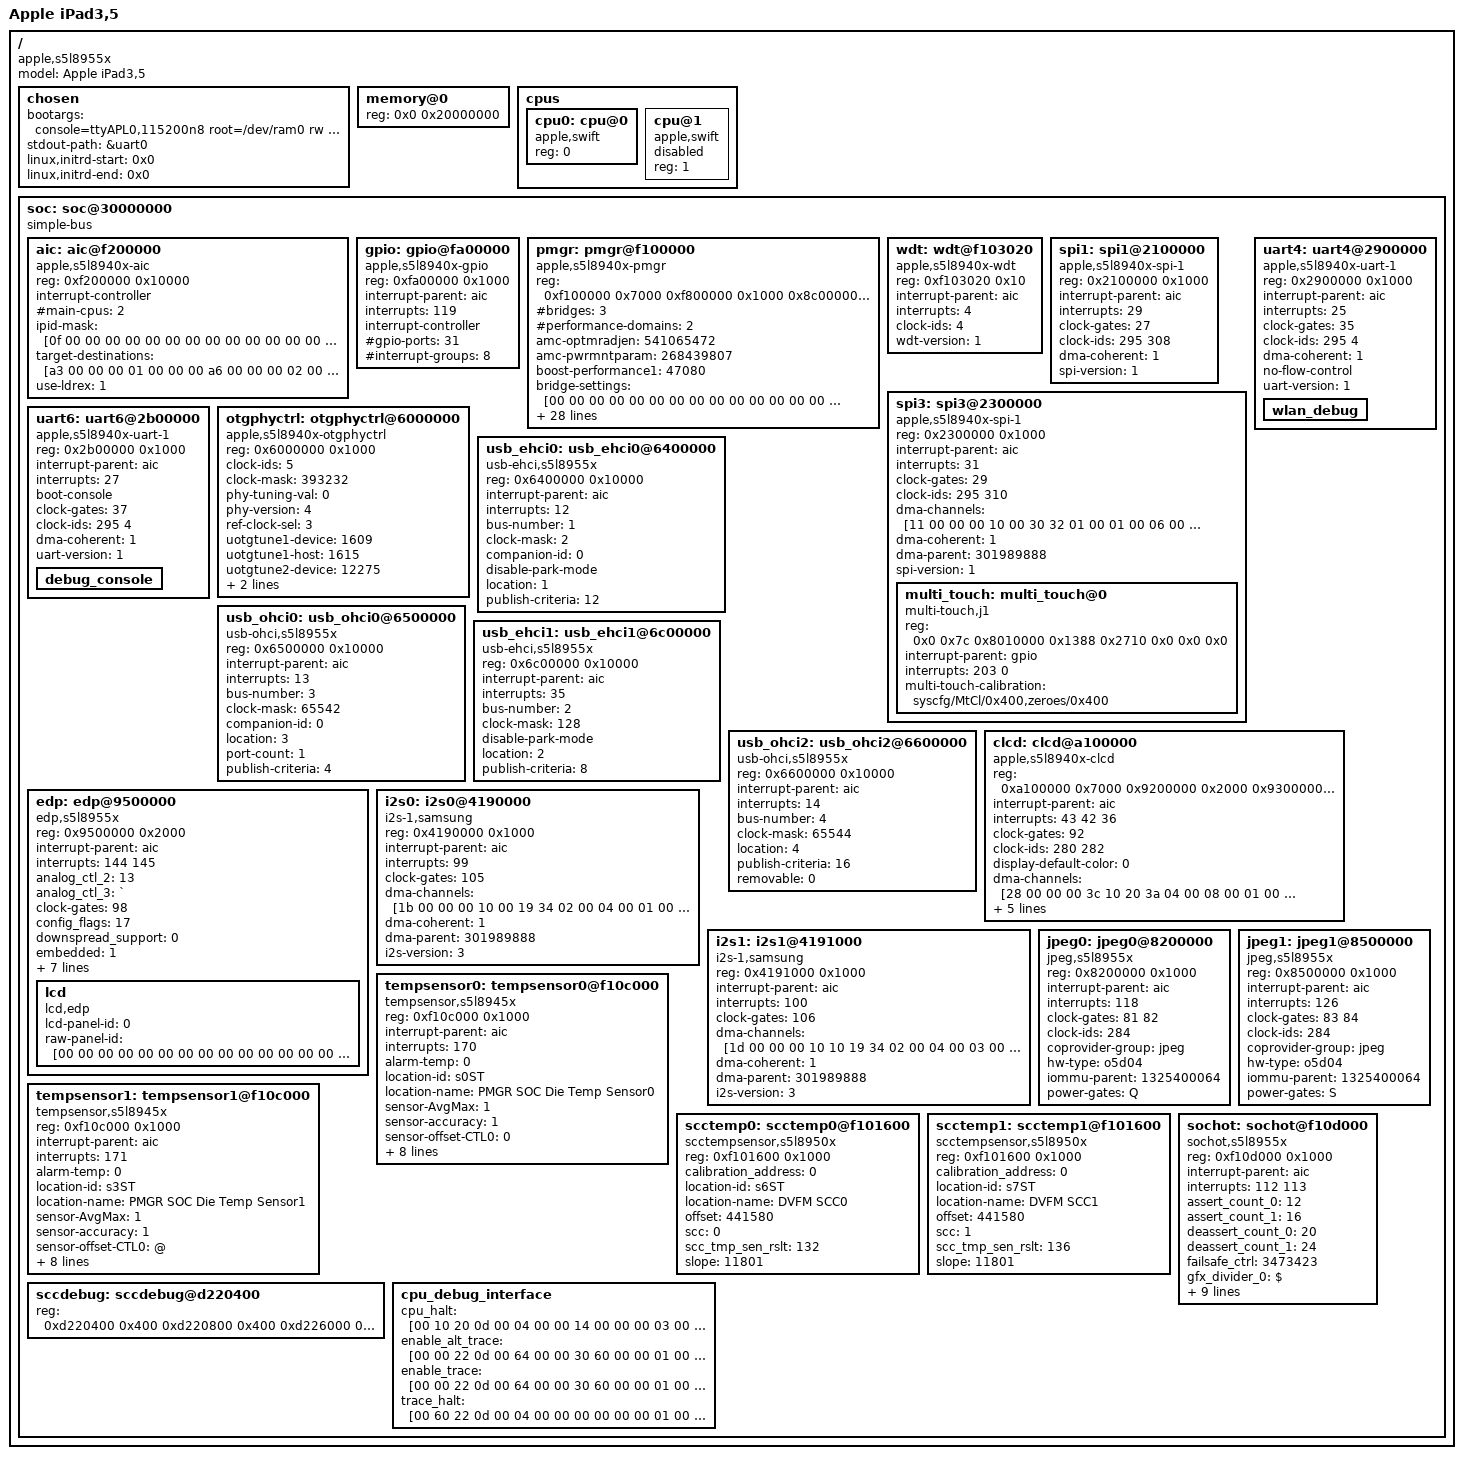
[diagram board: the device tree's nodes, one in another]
/*
 * Generated by adt_to_dts.py from Apple iBoot ADT.
 * Target: iPad2,5 (P105AP / S5L8942X, Apple A5).
 *
 * Register addresses under soc@30000000 use arm-io local bus
 * addresses (child 0 -> parent 0x30000000, size 0x10000000).
 * usb-complex children are flattened through usb-complex ranges
 * (child 0 -> 0x06100000, size 0x00600000) before insertion.
 *
 * memory@0, chosen/linux,initrd-*, and framebuffer values are zero
 * in the static ADT; patch them at boot from live iBoot state.
 */

/dts-v1/;

/ {
	compatible = "apple,s5l8955x", "apple,ipad3,5";
	model = "Apple iPad3,5";
	#address-cells = <1>;
	#size-cells = <1>;
	
	chosen {
		bootargs = "console=ttyAPL0,115200n8 root=/dev/ram0 rw earlyprintk";
		stdout-path = &uart0;
		linux,initrd-start = <0x0>;
		linux,initrd-end = <0x0>;
		/* ADT mac-address-bluetooth0 = [6d6163616464722f6274616464722c7379736366672f424d61632f36] */
		/* ADT mac-address-ethernet0 = [6d6163616464722f657468616464722c7379736366672f454d61632f36] */
		/* ADT mac-address-wifi0 = [6d6163616464722f77696669616464722c7379736366672f574d61632f36] */
	};
	
	memory@0 {
		device_type = "memory";
		reg = <0x0 0x20000000>; /* TODO: patch at boot; 512 MiB placeholder */
	};
	
	cpus {
		#address-cells = <1>;
		#size-cells = <0>;
		cpu0: cpu@0 {
			device_type = "cpu";
			compatible = "apple,swift";
			reg = <0>;
		};
		cpu@1 {
			device_type = "cpu";
			compatible = "apple,swift";
			reg = <1>;
			status = "disabled";
		};
	};
	
	soc: soc@30000000 {
		compatible = "simple-bus";
		#address-cells = <1>;
		#size-cells = <1>;
		ranges = <0x0 0x30000000 0x10000000>;
		
		aic: aic@f200000 {
			compatible = "apple,s5l8940x-aic";
			device_type = "interrupt-controller";
			reg = <0xf200000 0x10000>;
			interrupt-controller;
			#interrupt-cells = <1>;
			#address-cells = <0>;
			#main-cpus = <2>;
			ipid-mask = [0f 00 00 00 00 00 00 00 00 00 00 00 00 00 00 00 00 00 00 00 00 00 00 00];
			target-destinations = [a3 00 00 00 01 00 00 00 a6 00 00 00 02 00 00 00];
			use-ldrex = <1>;
		};
		
		gpio: gpio@fa00000 {
			compatible = "apple,s5l8940x-gpio", "apple,s5l8940x-gpio", "apple,s5l8940x-gpio";
			device_type = "interrupt-controller";
			reg = <0xfa00000 0x1000>;
			interrupt-parent = <&aic>;
			interrupts = <119>;
			interrupt-controller;
			#interrupt-cells = <2>;
			#address-cells = <0>;
			#gpio-ports = <31>;
			#interrupt-groups = <8>;
		};
		
		pmgr: pmgr@f100000 {
			compatible = "apple,s5l8940x-pmgr", "apple,s5l8940x-pmgr";
			reg = <0xf100000 0x7000 0xf800000 0x1000 0x8c00000 0x1000 0x8d00000 0x1000 0x8e00000 0x1000 0x8f00000 0x1000 0xa500000 0x1000 0xa600000 0x1000>;
			#bridges = <3>;
			#performance-domains = <2>;
			amc-optmradjen = <541065472>;
			amc-pwrmntparam = <268439807>;
			boost-performance1 = <47080>;
			bridge-settings = [00 00 00 00 00 00 00 00 00 00 00 00 00 00 00 00 00 00 00 00 00 00 00 00 00 00 00 00 00 00 00 00 00 00 00 00 00 00 00 00 00 00 00 00 00 00 00 00 00 00 00 00 00 00 00 00 00 00 00 00 00 00 00 00 00 00 00 00 00 00 00 00 00 00 00 00 00 00 00 00 00 00 00 00 00 00 00 00 00 00 00 00 00 00 00 00 00 00 00 00 00 00 00 00 00 00 00 00 00 00 00 00 00 00 00 00 00 00 00 00 00 00 00 00 00 00 00 00 00 00 00 00 00 00 00 00 00 00 00 00 00 00 00 00 00 00 00 00 00 00 00 00 00 00 00 00 00 00 00 00 00 00 00 00 00 00 00 00 00 00 00 00 00 00 00 00 00 00 00 00 00 00 00 00 00 00 00 00 00 00 00 00 00 00 00 00 00 00 00 00 00 00 00 00 00 00 00 00 00 00 00 00 00 00 00 00 00 00 00 00 00 00 00 00 00 00 00 00 00 00 00 00 00 00 00 00 00 00 00 00 00 00 00 00 00 00 00 00 00 00 00 00 00 00 00 00 00 00 00 00 00 00 00 00 00 00 00 00 00 00 00 00 00 00 00 00 00 00 00 00 00 00 00 00 00 00 00 00 00 00 00 00 00 00 00 00 00 00 00 00 00 00 00 00 00 00 00 00 00 00 00 00 00 00 00 00 00 00 00 00 00 00 00 00 00 00 00 00 00 00 00 00 00 00 00 00 00 00 00 00 00 00 00 00 00 00 00 00 00 00 00 00 00 00 00 00 00 00 00 00 00 00 00 00 00 00 00 00 00 00 00 00 00 00 00 00 00 00 00 00 00 00 00 00 00 00 00 00 00 00 00 00 00 00 00 00 00 00 00 00 00 00 00 00 00 00 00 00 00 00 00 00 00 00 00 00 00 00 00 00 00 00 00 00 00 00 00 00 00 00 00 00 00 00 00 00 00 00 00 00 00 00 00 00 00 00 00 00 00 00 00 00 00 00 00 00 00 00 00 00 00 00 00 00 00 00 00 00 00 00 00 00 00 00 00 00 00 00 00 00 00 00 00 00 00 00 00 00 00 00 00 00 00 00 00 00 00 00 00 00 00 00 00 00 00 00 00 00 00 00 00 00];
			clock-ids = <317 318 319>;
			cpu-max-core-count = <2>;
			device-clocks = [08 00 00 00 00 00 00 00 00 00 00 00 00 00 00 00 00 00 00 00 ed 7c 00 00 00 00 00 00 43 50 55 30 00 00 00 00 00 00 00 00 00 00 00 00 00 00 00 01 00 00 00 00 00 00 00 00 00 00 00 00 00 00 00 00 ed 7c 00 00 00 00 00 00 43 50 55 31 00 00 00 00 00 00 00 00 00 00 00 00 00 00 00 08 02 01 00 00 00 00 00 00 0b 00 00 00 00 00 00 00 00 00 00 00 00 00 00 00 48 50 45 52 46 2d 4e 52 54 00 00 00 00 00 00 00 00 00 00 09 02 02 00 00 00 00 00 00 13 18 00 00 00 00 00 00 00 00 00 00 00 00 00 00 48 50 45 52 46 2d 52 54 00 00 00 00 00 00 00 00 00 00 00 0a 00 00 00 00 09 00 00 00 14 00 00 00 00 00 00 00 00 00 00 00 00 00 00 00 48 50 45 52 46 2d 49 53 50 00 00 00 00 00 00 00 00 00 00 0b 00 00 00 00 00 00 00 00 28 00 00 00 00 00 00 00 00 00 05 00 00 00 00 00 41 55 44 49 4f 00 00 00 00 00 00 00 00 00 00 00 01 00 08 0e 00 00 00 00 00 00 00 00 00 00 00 00 00 00 00 00 00 00 00 00 00 00 00 00 52 47 42 4f 55 54 2d 4c 41 52 47 45 00 00 00 00 01 00 08 0f 00 00 00 00 00 00 00 00 00 00 00 00 00 00 00 00 00 00 00 00 00 00 00 00 44 55 41 4c 2d 44 49 53 50 4c 41 59 00 00 00 00 00 00 00 10 00 00 00 00 00 00 00 00 2f 00 00 00 00 00 00 00 00 00 00 00 00 00 00 00 53 44 49 4f 00 00 00 00 00 00 00 00 00 00 00 00 00 00 00 11 00 00 00 00 00 00 00 00 30 00 00 00 00 00 00 00 00 00 00 00 00 00 00 00 53 48 41 2d 31 00 00 00 00 00 00 00 00 00 00 00 00 00 00 12 00 00 00 00 00 00 00 00 31 00 00 00 00 00 00 00 00 00 00 00 00 00 00 00 53 48 41 2d 32 00 00 00 00 00 00 00 00 00 00 00 01 00 00 14 00 00 00 00 00 00 00 00 32 00 00 00 00 00 00 00 00 00 00 00 00 00 00 00 46 4d 49 30 00 00 00 00 00 00 00 00 00 00 00 00 00 00 00 15 00 00 00 00 00 00 00 00 33 00 00 00 00 00 00 00 00 00 00 00 00 00 00 00 46 4d 49 30 2d 42 43 48 00 00 00 00 00 00 00 00 01 00 00 16 00 00 00 00 00 00 00 00 34 00 00 00 00 00 00 00 00 00 00 00 00 00 00 00 46 4d 49 31 00 00 00 00 00 00 00 00 00 00 00 00 00 00 00 17 00 00 00 00 00 00 00 00 35 00 00 00 00 00 00 00 00 00 00 00 00 00 00 00 46 4d 49 31 2d 42 43 48 00 00 00 00 00 00 00 00 00 00 00 18 00 00 00 00 00 00 00 00 36 00 00 00 00 00 00 00 00 00 00 00 00 00 00 00 46 4d 49 2d 44 4c 4c 00 00 00 00 00 00 00 00 00 00 00 00 1a 00 00 00 00 00 00 00 00 39 00 00 00 00 00 00 00 00 00 00 00 00 00 00 00 53 50 49 30 00 00 00 00 00 00 00 00 00 00 00 00 00 00 00 1b 00 00 00 00 00 00 00 00 3a 00 00 00 00 00 00 00 00 00 00 00 00 00 00 00 53 50 49 31 00 00 00 00 00 00 00 00 00 00 00 00 00 00 00 1c 00 00 00 00 00 00 00 00 3b 00 00 00 00 00 00 00 00 00 00 00 00 00 00 00 53 50 49 32 00 00 00 00 00 00 00 00 00 00 00 00 00 00 00 1d 00 00 00 00 00 00 00 00 3c 00 00 00 00 00 00 00 00 00 00 00 00 00 00 00 53 50 49 33 00 00 00 00 00 00 00 00 00 00 00 00 00 00 00 1e 00 00 00 00 00 00 00 00 3d 00 00 00 00 00 00 00 00 00 00 00 00 00 00 00 53 50 49 34 00 00 00 00 00 00 00 00 00 00 00 00 00 00 03 1f 00 00 00 00 00 00 00 00 3e 00 00 00 00 00 00 00 00 00 00 00 00 00 00 00 55 41 52 54 30 00 00 00 00 00 00 00 00 00 00 00 00 00 00 20 00 00 00 00 00 00 00 00 3f 00 00 00 00 00 00 00 00 00 00 00 00 00 00 00 55 41 52 54 31 00 00 00 00 00 00 00 00 00 00 00 00 00 00 21 00 00 00 00 00 00 00 00 40 00 00 00 00 00 00 00 00 00 00 00 00 00 00 00 55 41 52 54 32 00 00 00 00 00 00 00 00 00 00 00 00 00 00 22 00 00 00 00 00 00 00 00 41 00 00 00 00 00 00 00 00 00 00 00 00 00 00 00 55 41 52 54 33 00 00 00 00 00 00 00 00 00 00 00 00 00 00 23 00 00 00 00 00 00 00 00 42 00 00 00 00 00 00 00 00 00 00 00 00 00 00 00 55 41 52 54 34 00 00 00 00 00 00 00 00 00 00 00 00 00 00 24 00 00 00 00 00 00 00 00 43 00 00 00 00 00 00 00 00 00 00 00 00 00 00 00 55 41 52 54 35 00 00 00 00 00 00 00 00 00 00 00 00 00 03 25 00 00 00 00 00 00 00 00 44 00 00 00 00 00 00 00 00 00 00 00 00 00 00 00 55 41 52 54 36 00 00 00 00 00 00 00 00 00 00 00 00 00 00 28 00 00 00 00 00 00 00 00 45 00 00 00 00 00 00 00 00 00 00 00 00 00 00 00 50 4b 45 00 00 00 00 00 00 00 00 00 00 00 00 00 00 00 00 29 00 00 00 00 00 00 00 00 46 00 00 00 00 00 00 00 00 00 00 00 00 00 00 00 49 32 43 30 00 00 00 00 00 00 00 00 00 00 00 00 00 00 00 2a 00 00 00 00 00 00 00 00 47 00 00 00 00 00 00 00 00 00 00 00 00 00 00 00 49 32 43 31 00 00 00 00 00 00 00 00 00 00 00 00 00 00 00 2b 00 00 00 00 00 00 00 00 48 00 00 00 00 00 00 00 00 00 00 00 00 00 00 00 49 32 43 32 00 00 00 00 00 00 00 00 00 00 00 00 00 00 00 2c 00 00 00 00 00 00 00 00 49 00 00 00 00 00 00 00 00 00 00 00 00 00 00 00 50 57 4d 00 00 00 00 00 00 00 00 00 00 00 00 00 00 00 03 30 00 00 00 00 00 00 00 00 1e 00 00 00 00 00 00 00 51 f8 3d 00 00 00 00 00 43 44 49 4f 00 00 00 00 00 00 00 00 00 00 00 00 00 00 03 31 00 00 00 00 00 00 00 00 1f 00 00 00 00 00 00 00 00 00 00 00 00 00 00 00 43 44 4d 41 00 00 00 00 00 00 00 00 00 00 00 00 00 00 10 32 00 00 00 00 00 00 00 00 20 00 00 00 00 00 00 00 00 00 00 00 00 00 00 00 49 4f 50 00 00 00 00 00 00 00 00 00 00 00 00 00 00 00 00 04 00 00 00 00 00 00 00 00 21 00 00 00 00 00 00 00 00 00 00 00 00 00 00 00 55 50 45 52 46 00 00 00 00 00 00 00 00 00 00 00 05 00 00 05 00 00 00 00 04 00 00 00 24 00 00 00 00 00 00 00 00 00 00 00 00 00 00 00 55 53 42 31 31 48 4f 53 54 00 00 00 00 00 00 00 00 00 00 06 00 00 00 00 04 00 00 00 27 00 00 00 00 00 00 00 00 00 00 00 00 00 00 00 55 53 42 52 45 47 30 00 00 00 00 00 00 00 00 00 00 00 00 07 00 00 00 00 00 00 00 00 00 00 00 00 5a 00 00 00 00 00 00 00 00 00 00 00 55 53 42 2d 46 52 45 45 2d 43 4c 4b 00 00 00 00 00 00 00 34 00 00 00 00 04 06 00 00 00 00 00 00 00 00 00 00 00 00 00 00 00 00 00 00 55 53 42 2d 50 48 59 00 00 00 00 00 00 00 00 00 01 00 00 35 00 00 00 00 04 00 00 00 22 00 00 00 00 00 00 00 00 00 00 00 00 00 00 00 55 53 42 4f 54 47 30 00 00 00 00 00 00 00 00 00 00 00 00 36 00 00 00 00 04 07 00 00 23 00 00 00 00 00 00 00 00 00 00 00 00 00 00 00 55 53 42 32 48 4f 53 54 30 00 00 00 00 00 00 00 00 00 00 37 00 00 00 00 04 06 00 00 25 00 00 00 00 00 00 00 00 00 00 00 00 00 00 00 55 53 42 32 48 4f 53 54 30 5f 4f 48 43 49 00 00 00 00 00 38 00 00 00 00 04 05 06 00 26 00 00 00 00 00 00 00 00 00 00 00 00 00 00 00 55 53 42 31 31 48 4f 53 54 5f 4f 48 43 49 00 00 00 00 00 3a 00 00 00 00 04 07 00 00 50 00 00 00 00 00 00 00 00 00 00 00 00 00 00 00 55 53 42 32 48 4f 53 54 31 00 00 00 00 00 00 00 00 00 00 3b 00 00 00 00 04 06 00 00 51 00 00 00 00 00 00 00 00 00 00 00 00 00 00 00 55 53 42 32 48 4f 53 54 31 5f 4f 48 43 49 00 00 00 00 00 3c 00 00 00 00 00 00 00 00 00 00 00 00 53 00 00 00 00 00 00 00 00 00 00 00 55 53 42 2d 50 48 59 30 2d 43 4c 4b 00 00 00 00 00 00 00 3d 00 00 00 00 00 00 00 00 00 00 00 00 59 00 00 00 00 00 00 00 00 00 00 00 55 53 42 2d 50 48 59 31 2d 43 4c 4b 00 00 00 00 01 00 00 3e 00 00 00 00 00 00 00 00 00 00 00 00 00 00 00 00 00 00 00 00 00 00 00 00 55 53 42 32 2d 46 41 53 54 00 00 00 00 00 00 00 01 00 00 40 00 00 00 00 00 00 00 00 09 0a 00 00 00 00 00 00 00 00 c4 09 00 00 00 00 47 46 58 00 00 00 00 00 00 00 00 00 00 00 00 00 80 00 00 41 00 00 00 00 00 00 00 00 00 00 00 00 00 00 00 00 00 00 00 00 00 00 00 00 47 46 58 2d 46 41 53 54 00 00 00 00 00 00 00 00 00 00 00 48 02 00 00 00 08 00 00 00 00 00 00 00 00 00 00 00 00 00 00 00 00 00 00 00 44 41 52 54 2d 4e 52 54 00 00 00 00 00 00 00 00 01 00 00 49 00 00 00 00 08 00 00 00 0c 00 00 00 00 00 00 00 00 00 00 00 00 00 00 00 56 44 45 43 00 00 00 00 00 00 00 00 00 00 00 00 80 00 00 4a 00 00 00 00 00 00 00 00 00 00 00 00 00 00 00 00 00 00 00 00 00 00 00 00 56 44 45 43 2d 46 41 53 54 00 00 00 00 00 00 00 01 00 00 4b 00 00 00 00 08 00 00 00 12 00 00 00 00 00 00 00 00 00 64 00 00 00 00 00 56 45 4e 43 00 00 00 00 00 00 00 00 00 00 00 00 80 01 00 4c 00 00 00 00 00 00 00 00 00 00 00 00 00 00 00 00 00 00 64 00 00 00 00 00 56 45 4e 43 2d 46 41 53 54 00 00 00 00 00 00 00 01 00 00 4d 00 00 00 00 08 00 00 00 0d 00 00 00 00 00 00 00 00 00 00 00 00 00 00 00 53 43 41 4c 45 52 30 00 00 00 00 00 00 00 00 00 80 00 00 4e 00 00 00 00 00 00 00 00 00 00 00 00 00 00 00 00 00 00 00 00 00 00 00 00 53 43 41 4c 45 52 30 2d 46 41 53 54 00 00 00 00 01 00 00 4f 00 00 00 00 08 00 00 00 0e 00 00 00 00 00 00 00 00 00 00 00 00 00 00 00 53 43 41 4c 45 52 31 00 00 00 00 00 00 00 00 00 80 00 00 50 00 00 00 00 00 00 00 00 00 00 00 00 00 00 00 00 00 00 00 00 00 00 00 00 53 43 41 4c 45 52 31 2d 46 41 53 54 00 00 00 00 01 00 00 51 00 00 00 00 08 00 00 00 0f 00 00 00 00 00 00 00 00 00 00 00 00 00 00 00 4a 50 45 47 30 00 00 00 00 00 00 00 00 00 00 00 80 00 00 52 00 00 00 00 00 00 00 00 00 00 00 00 00 00 00 00 00 00 00 00 00 00 00 00 4a 50 45 47 30 2d 46 41 53 54 00 00 00 00 00 00 01 00 00 53 00 00 00 00 08 00 00 00 10 00 00 00 00 00 00 00 00 00 00 00 00 00 00 00 4a 50 45 47 31 00 00 00 00 00 00 00 00 00 00 00 80 00 00 54 00 00 00 00 00 00 00 00 00 00 00 00 00 00 00 00 00 00 00 00 00 00 00 00 4a 50 45 47 31 2d 46 41 53 54 00 00 00 00 00 00 00 00 01 5c 03 00 00 00 09 0f 00 00 16 1a 00 00 00 00 00 00 00 00 c4 01 00 00 00 00 43 4c 43 44 00 00 00 00 00 00 00 00 00 00 00 00 00 00 01 5e 03 00 00 00 09 0e 0f 00 17 1c 00 00 00 00 00 00 00 00 00 00 00 00 00 00 52 47 42 4f 55 54 00 00 00 00 00 00 00 00 00 00 00 00 04 5f 00 00 00 00 0e 00 00 00 00 00 00 00 00 00 00 00 00 00 00 00 00 00 00 00 52 47 42 4f 55 54 2d 53 4d 41 4c 4c 00 00 00 00 00 00 01 60 00 00 00 00 09 00 00 00 1d 00 00 00 00 00 00 00 00 00 00 00 00 00 00 00 44 50 4c 49 4e 4b 00 00 00 00 00 00 00 00 00 00 00 00 00 61 00 00 00 00 09 00 00 00 1b 00 00 00 00 00 00 00 00 00 00 00 00 00 00 00 54 56 2d 4f 55 54 00 00 00 00 00 00 00 00 00 00 00 00 01 62 00 00 00 00 09 00 00 00 15 00 00 00 00 00 00 00 00 00 00 00 00 00 00 00 45 44 50 00 00 00 00 00 00 00 00 00 00 00 00 00 00 00 00 64 00 00 00 00 0a 00 00 00 00 00 00 00 00 00 00 00 00 00 00 00 00 00 00 00 44 41 52 54 2d 52 54 00 00 00 00 00 00 00 00 00 01 00 10 65 00 00 00 00 0a 00 00 00 00 00 00 00 00 00 00 00 00 00 c8 00 00 00 00 00 49 53 50 00 00 00 00 00 00 00 00 00 00 00 00 00 00 00 10 68 00 00 00 00 0b 00 00 00 00 00 00 00 00 00 00 00 00 00 00 00 00 00 00 00 41 45 32 00 00 00 00 00 00 00 00 00 00 00 00 00 00 00 00 69 00 00 00 00 0b 00 00 00 29 00 00 00 00 00 00 00 00 00 00 00 00 00 00 00 49 32 53 30 00 00 00 00 00 00 00 00 00 00 00 00 00 00 00 6a 00 00 00 00 0b 00 00 00 2a 00 00 00 00 00 00 00 00 00 00 00 00 00 00 00 49 32 53 31 00 00 00 00 00 00 00 00 00 00 00 00 00 00 00 6b 00 00 00 00 0b 00 00 00 2b 00 00 00 00 00 00 00 00 00 00 00 00 00 00 00 49 32 53 32 00 00 00 00 00 00 00 00 00 00 00 00 00 00 00 6c 00 00 00 00 0b 00 00 00 2c 00 00 00 00 00 00 00 00 00 00 00 00 00 00 00 49 32 53 33 2f 4d 43 41 31 00 00 00 00 00 00 00 00 00 00 6d 00 00 00 00 0b 00 00 00 2d 00 00 00 00 00 00 00 00 00 00 00 00 00 00 00 53 50 44 49 46 00 00 00 00 00 00 00 00 00 00 00 00 00 00 6e 00 00 00 00 0b 00 00 00 38 00 00 00 00 00 00 00 00 00 00 00 00 00 00 00 4d 43 41 00 00 00 00 00 00 00 00 00 00 00 00 00 05 00 00 7e 00 00 00 00 00 00 00 00 4c 00 00 00 00 00 00 00 00 00 00 00 00 00 00 00 53 57 49 00 00 00 00 00 00 00 00 00 00 00 00 00 00 00 03 7f 00 00 00 00 00 00 00 00 4d 00 00 00 00 00 00 00 00 00 00 00 00 00 00 00 44 57 49 00 00 00 00 00 00 00 00 00 00 00 00 00];
			device-clocks-max = <128>;
			device-clocks-min = <16>;
			dvb-boost-timeout = <4000>;
			dvb-relax-timeout = <12000>;
			dvb-thermal-period = <1000000>;
			dvc-active-timeout = <4000>;
			dvc-grace-period = "d";
			dvd-period = <8000>;
			dvd-threshold = <1000>;
			firmware-m-perf-states = [00 00 00 00 00 00 00 00 00 00 00 00 00 00 00 00];
			firmware-p-perf-state = <0>;
			firmware-v-perf-states = [00 00 00 00 00 00 00 00];
			nominal-performance0 = <65536>;
			nominal-performance1 = <54613>;
			pdmvr-rules = <16842754>;
			performance-domain-features = [01 00 01 00 00 07 01 00];
			turbolag-timeout = <100000>;
			voltage-states0 = [00 00 01 00 00 00 00 00 00 80 00 00 00 00 00 00];
			voltage-states1 = [00 00 00 00 00 00 00 00 00 00 00 00 00 00 00 00 00 00 00 00 00 00 00 00 00 00 00 00 00 00 00 00 00 00 00 00 00 00 00 00 00 00 00 00 00 00 00 00 00 00 00 00 00 00 00 00 00 00 00 00 00 00 00 00];
		};
		
		wdt: wdt@f103020 {
			compatible = "apple,s5l8940x-wdt", "apple,s5l8940x-wdt", "apple,s5l8940x-wdt", "apple,s5l8940x-wdt";
			device_type = "wdt";
			reg = <0xf103020 0x10>;
			interrupt-parent = <&aic>;
			interrupts = <4>;
			clock-ids = <4>;
			wdt-version = <1>;
		};
		
		spi1: spi1@2100000 {
			compatible = "apple,s5l8940x-spi-1";
			device_type = "spi";
			reg = <0x2100000 0x1000>;
			interrupt-parent = <&aic>;
			interrupts = <29>;
			#address-cells = <1>;
			#size-cells = <7>;
			clock-gates = <27>;
			clock-ids = <295 308>;
			dma-coherent = <1>;
			spi-version = <1>;
		};
		
		spi3: spi3@2300000 {
			compatible = "apple,s5l8940x-spi-1";
			device_type = "spi";
			reg = <0x2300000 0x1000>;
			interrupt-parent = <&aic>;
			interrupts = <31>;
			#address-cells = <1>;
			#size-cells = <7>;
			clock-gates = <29>;
			clock-ids = <295 310>;
			dma-channels = [11 00 00 00 10 00 30 32 01 00 01 00 06 00 00 00 12 00 00 00 20 00 40 32 01 00 01 00 07 00 00 00];
			dma-coherent = <1>;
			dma-parent = <301989888>;
			spi-version = <1>;
			multi_touch: multi_touch@0 {
				compatible = "multi-touch,j1";
				device_type = "multi-touch";
				reg = <0x0 0x7c 0x8010000 0x1388 0x2710 0x0 0x0 0x0>;
				interrupt-parent = <&gpio>;
				interrupts = <203 0>;
				multi-touch-calibration = "syscfg/MtCl/0x400,zeroes/0x400";
			};
			
		};
		
		uart4: uart4@2900000 {
			compatible = "apple,s5l8940x-uart-1";
			device_type = "uart";
			reg = <0x2900000 0x1000>;
			interrupt-parent = <&aic>;
			interrupts = <25>;
			clock-gates = <35>;
			clock-ids = <295 4>;
			dma-coherent = <1>;
			no-flow-control;
			uart-version = <1>;
			wlan_debug: wlan_debug {
				device_type = "wlan-debug";
			};
			
		};
		
		uart6: uart6@2b00000 {
			compatible = "apple,s5l8940x-uart-1";
			device_type = "uart";
			reg = <0x2b00000 0x1000>;
			interrupt-parent = <&aic>;
			interrupts = <27>;
			boot-console;
			clock-gates = <37>;
			clock-ids = <295 4>;
			dma-coherent = <1>;
			uart-version = <1>;
			debug_console: debug_console {
			};
			
		};
		
		otgphyctrl: otgphyctrl@6000000 {
			compatible = "apple,s5l8940x-otgphyctrl", "apple,s5l8940x-otgphyctrl", "apple,s5l8940x-otgphyctrl";
			device_type = "otgphyctrl";
			reg = <0x6000000 0x1000>;
			clock-ids = <5>;
			clock-mask = <393232>;
			phy-tuning-val = <0>;
			phy-version = <4>;
			ref-clock-sel = <3>;
			uotgtune1-device = <1609>;
			uotgtune1-host = <1615>;
			uotgtune2-device = <12275>;
			uotgtune2-host = <28147>;
			usbhostset-en-incrx = <224>;
		};
		
		usb_ehci0: usb_ehci0@6400000 {
			compatible = "usb-ehci,s5l8955x", "usb-ehci,s5l8950x", "usb-synopsys_ehci,s5l8930x";
			device_type = "usb-ehci";
			reg = <0x6400000 0x10000>;
			interrupt-parent = <&aic>;
			interrupts = <12>;
			bus-number = <1>;
			clock-mask = <2>;
			companion-id = <0>;
			disable-park-mode;
			location = <1>;
			publish-criteria = <12>;
		};
		
		usb_ohci0: usb_ohci0@6500000 {
			compatible = "usb-ohci,s5l8955x", "usb-ohci,s5l8950x", "usb-ohci,s5l8930x";
			device_type = "usb-ohci";
			reg = <0x6500000 0x10000>;
			interrupt-parent = <&aic>;
			interrupts = <13>;
			bus-number = <3>;
			clock-mask = <65542>;
			companion-id = <0>;
			location = <3>;
			port-count = <1>;
			publish-criteria = <4>;
		};
		
		usb_ehci1: usb_ehci1@6c00000 {
			compatible = "usb-ehci,s5l8955x", "usb-ehci,s5l8950x", "usb-synopsys_ehci,s5l8930x";
			device_type = "usb-ehci";
			reg = <0x6c00000 0x10000>;
			interrupt-parent = <&aic>;
			interrupts = <35>;
			bus-number = <2>;
			clock-mask = <128>;
			disable-park-mode;
			location = <2>;
			publish-criteria = <8>;
		};
		
		usb_ohci2: usb_ohci2@6600000 {
			compatible = "usb-ohci,s5l8955x", "usb-ohci,s5l8950x", "usb-ohci,s5l8930x";
			device_type = "usb-ohci";
			reg = <0x6600000 0x10000>;
			interrupt-parent = <&aic>;
			interrupts = <14>;
			bus-number = <4>;
			clock-mask = <65544>;
			location = <4>;
			publish-criteria = <16>;
			removable = <0>;
		};
		
		clcd: clcd@a100000 {
			compatible = "apple,s5l8940x-clcd";
			device_type = "clcd";
			reg = <0xa100000 0x7000 0x9200000 0x2000 0x9300000 0x1000 0x9900000 0x1000 0x9380000 0x1000 0x9a00000 0x7000 0x9b00000 0x4000>;
			interrupt-parent = <&aic>;
			interrupts = <43 42 36>;
			clock-gates = <92>;
			clock-ids = <280 282>;
			display-default-color = <0>;
			dma-channels = [28 00 00 00 3c 10 20 3a 04 00 08 00 01 00 00 00];
			dma-coherent = [00 00 00 00 01 00 00 00];
			dma-parent = <301989888>;
			dot-pitch = <0>;
			enable-aap;
			power-gates = "\\";
		};
		
		edp: edp@9500000 {
			compatible = "edp,s5l8955x", "edp,s5l8945x";
			device_type = "edp";
			reg = <0x9500000 0x2000>;
			interrupt-parent = <&aic>;
			interrupts = <144 145>;
			analog_ctl_2 = <13>;
			analog_ctl_3 = "`";
			clock-gates = <98>;
			config_flags = <17>;
			downspread_support = <0>;
			embedded = <1>;
			max_lane_count = <4>;
			max_link_rate = <10>;
			min_lane_count = <4>;
			min_link_rate = <6>;
			pll_ctl = <20>;
			power-gates = "b";
			pre_configured = <0>;
			lcd: lcd {
				compatible = "lcd,edp";
				device_type = "lcd";
				#address-cells = <1>;
				#size-cells = <1>;
				lcd-panel-id = <0>;
				raw-panel-id = [00 00 00 00 00 00 00 00 00 00 00 00 00 00 00 00];
			};
			
		};
		
		i2s0: i2s0@4190000 {
			compatible = "i2s-1,samsung";
			device_type = "i2s";
			reg = <0x4190000 0x1000>;
			interrupt-parent = <&aic>;
			interrupts = <99>;
			#address-cells = <0>;
			#size-cells = <8>;
			clock-gates = <105>;
			dma-channels = [1b 00 00 00 10 00 19 34 02 00 04 00 01 00 00 00 1c 00 00 00 38 00 19 34 02 00 04 00 00 00 00 00 1b 00 00 00 10 00 19 34 04 00 04 00 01 00 00 00 1c 00 00 00 38 00 19 34 04 00 04 00 00 00 00 00];
			dma-coherent = <1>;
			dma-parent = <301989888>;
			i2s-version = <3>;
		};
		
		i2s1: i2s1@4191000 {
			compatible = "i2s-1,samsung";
			device_type = "i2s";
			reg = <0x4191000 0x1000>;
			interrupt-parent = <&aic>;
			interrupts = <100>;
			#address-cells = <0>;
			#size-cells = <8>;
			clock-gates = <106>;
			dma-channels = [1d 00 00 00 10 10 19 34 02 00 04 00 03 00 00 00 1e 00 00 00 38 10 19 34 02 00 04 00 02 00 00 00 1d 00 00 00 10 10 19 34 04 00 04 00 03 00 00 00 1e 00 00 00 38 10 19 34 04 00 04 00 02 00 00 00];
			dma-coherent = <1>;
			dma-parent = <301989888>;
			i2s-version = <3>;
		};
		
		jpeg0: jpeg0@8200000 {
			compatible = "jpeg,s5l8955x", "jpeg,s5l8950x", "jpeg,s5l8920x";
			device_type = "jpeg";
			reg = <0x8200000 0x1000>;
			interrupt-parent = <&aic>;
			interrupts = <118>;
			clock-gates = <81 82>;
			clock-ids = <284>;
			coprovider-group = "jpeg";
			hw-type = "o5d04";
			iommu-parent = <1325400064>;
			power-gates = "Q";
		};
		
		jpeg1: jpeg1@8500000 {
			compatible = "jpeg,s5l8955x", "jpeg,s5l8950x", "jpeg,s5l8920x";
			device_type = "jpeg";
			reg = <0x8500000 0x1000>;
			interrupt-parent = <&aic>;
			interrupts = <126>;
			clock-gates = <83 84>;
			clock-ids = <284>;
			coprovider-group = "jpeg";
			hw-type = "o5d04";
			iommu-parent = <1325400064>;
			power-gates = "S";
		};
		
		tempsensor0: tempsensor0@f10c000 {
			compatible = "tempsensor,s5l8945x";
			device_type = "tempsensor0";
			reg = <0xf10c000 0x1000>;
			interrupt-parent = <&aic>;
			interrupts = <170>;
			alarm-temp = <0>;
			location-id = "s0ST";
			location-name = "PMGR SOC Die Temp Sensor0";
			sensor-AvgMax = <1>;
			sensor-accuracy = <1>;
			sensor-offset-CTL0 = <0>;
			sensor-offset-CTL1 = <4>;
			sensor-offset-CTL2 = <8>;
			sensor-offset-fuseslope = <12>;
			sensor-offset-readBK = <16>;
			sensor-offset-readBK1 = <20>;
			sensor-offset-readCnt = <28>;
			sensor-offset-readSum = <24>;
			sensor-offset-statMask = <16>;
		};
		
		tempsensor1: tempsensor1@f10c000 {
			compatible = "tempsensor,s5l8945x";
			device_type = "tempsensor1";
			reg = <0xf10c000 0x1000>;
			interrupt-parent = <&aic>;
			interrupts = <171>;
			alarm-temp = <0>;
			location-id = "s3ST";
			location-name = "PMGR SOC Die Temp Sensor1";
			sensor-AvgMax = <1>;
			sensor-accuracy = <1>;
			sensor-offset-CTL0 = "@";
			sensor-offset-CTL1 = "D";
			sensor-offset-CTL2 = "H";
			sensor-offset-fuseslope = "L";
			sensor-offset-readBK = "P";
			sensor-offset-readBK1 = "T";
			sensor-offset-readCnt = "\\";
			sensor-offset-readSum = "X";
			sensor-offset-statMask = <16>;
		};
		
		scctemp0: scctemp0@f101600 {
			compatible = "scctempsensor,s5l8950x";
			device_type = "scctemp0";
			reg = <0xf101600 0x1000>;
			calibration_address = <0>;
			location-id = "s6ST";
			location-name = "DVFM SCC0";
			offset = <441580>;
			scc = <0>;
			scc_tmp_sen_rslt = <132>;
			slope = <11801>;
		};
		
		scctemp1: scctemp1@f101600 {
			compatible = "scctempsensor,s5l8950x";
			device_type = "scctemp1";
			reg = <0xf101600 0x1000>;
			calibration_address = <0>;
			location-id = "s7ST";
			location-name = "DVFM SCC1";
			offset = <441580>;
			scc = <1>;
			scc_tmp_sen_rslt = <136>;
			slope = <11801>;
		};
		
		sochot: sochot@f10d000 {
			compatible = "sochot,s5l8955x";
			device_type = "sochot";
			reg = <0xf10d000 0x1000>;
			interrupt-parent = <&aic>;
			interrupts = <112 113>;
			assert_count_0 = <12>;
			assert_count_1 = <16>;
			deassert_count_0 = <20>;
			deassert_count_1 = <24>;
			failsafe_ctrl = <3473423>;
			gfx_divider_0 = "$";
			gfx_divider_1 = "(";
			mitigation_mode = <0>;
			scc_divider_0 = ",";
			scc_divider_1 = "0";
			sochot_ctl = <0>;
			sochot_temp0 = "i";
			sochot_temp1 = "s";
			trip_temp_0 = <4>;
			trip_temp_1 = <8>;
		};
		
		sccdebug: sccdebug@d220400 {
			device_type = "sccdebug";
			reg = <0xd220400 0x400 0xd220800 0x400 0xd226000 0x1000>;
		};
		
		cpu_debug_interface: cpu_debug_interface {
			device_type = "cpu-debug-interface";
			cpu_halt = [00 10 20 0d 00 04 00 00 14 00 00 00 03 00 00 00];
			enable_alt_trace = [00 00 22 0d 00 64 00 00 30 60 00 00 01 00 00 00 00 60 00 00 00 00 00 00 00 05 00 00 14 00 00 00 00 09 00 00 14 00 00 00 2c 04 00 00 00 00 00 00 2c 08 00 00 00 00 00 00 30 60 00 00 01 01 00 00];
			enable_trace = [00 00 22 0d 00 64 00 00 30 60 00 00 01 00 00 00 00 05 00 00 11 00 00 00 00 09 00 00 11 00 00 00 2c 04 00 00 91 00 00 00 2c 08 00 00 91 00 00 00 30 60 00 00 01 01 00 00];
			trace_halt = [00 60 22 0d 00 04 00 00 00 00 00 00 01 00 00 00];
		};
		
	};
	
};
